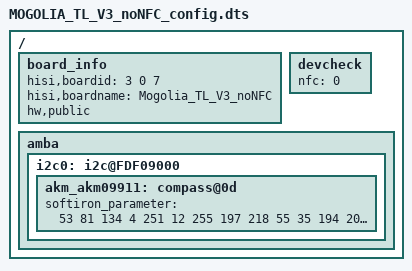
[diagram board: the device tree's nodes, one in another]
/*
 * Hisilicon Ltd.
 *
 * A15x4 A7x4
 *
 * It is only a demo for hisilicon hi3630 board. You show change the
 * address of each node according to datasheet.
 */

/dts-v1/;

/include/ "huawei-sensor.dtsi"

/include/ "MOGOLIA_TL_V3_config.dtsi"
/include/ "hisi_3630_pin_MOGOLIA_TL_V3_noNFC.dtsi"
/include/ "hisi_3630_modem_MOGOLIA_TL_V3_noNFC.dtsi"
/ {
	board_info: board_info {
		hisi,boardid = <3 0 7>;
		hisi,boardname = "Mogolia_TL_V3_noNFC";
		hw,public;
	};

	devcheck: devcheck {
		nfc = <0>;
	};
	amba{
        i2c0: i2c@FDF09000{
            akm_akm09911:compass@0d{
                softiron_parameter = <53 81 134 4 251 12 255 197 218 55 35 194 201 129 255 167 255 5 20 151 197 252 226 116 11 197 91>;
                };
	    };	
    };
};
